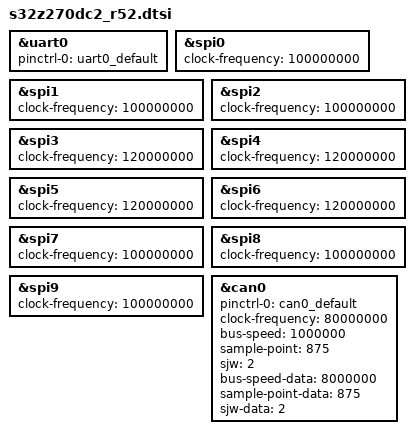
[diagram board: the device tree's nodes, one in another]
/*
 * Copyright 2022 NXP
 *
 * SPDX-License-Identifier: Apache-2.0
 */

#include <arm/nxp/nxp_s32z27x_r52.dtsi>
#include "s32z270dc2_r52-pinctrl.dtsi"

&uart0 {
	pinctrl-0 = <&uart0_default>;
	pinctrl-names = "default";
	status = "okay";
};

&spi0 {
	clock-frequency = <100000000>;
};

&spi1 {
	clock-frequency = <100000000>;
};

&spi2 {
	clock-frequency = <100000000>;
};

&spi3 {
	clock-frequency = <120000000>;
};

&spi4 {
	clock-frequency = <120000000>;
};

&spi5 {
	clock-frequency = <120000000>;
};

&spi6 {
	clock-frequency = <120000000>;
};

&spi7 {
	clock-frequency = <100000000>;
};

&spi8 {
	clock-frequency = <100000000>;
};

&spi9 {
	clock-frequency = <100000000>;
};

&can0 {
	pinctrl-0 = <&can0_default>;
	pinctrl-names = "default";
	clock-frequency = <80000000>;
	bus-speed = <1000000>;
	sample-point = <875>;
	sjw = <2>;
	bus-speed-data = <8000000>;
	sample-point-data = <875>;
	sjw-data = <2>;
};
